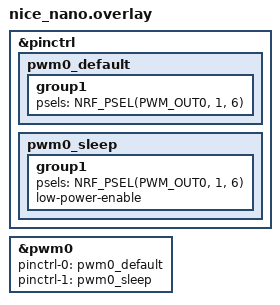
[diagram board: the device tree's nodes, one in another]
#include <dt-bindings/pwm/pwm.h>

&pinctrl {
    pwm0_default: pwm0_default {
        group1 {
            psels = <NRF_PSEL(PWM_OUT0, 1, 6)>;
        };
    };

    pwm0_sleep: pwm0_sleep {
        group1 {
            psels = <NRF_PSEL(PWM_OUT0, 1, 6)>;
            low-power-enable;
        };
    };
};

&pwm0 {
    pinctrl-0 = <&pwm0_default>;
    pinctrl-1 = <&pwm0_sleep>;
    pinctrl-names = "default", "sleep";
    status = "okay";
};
